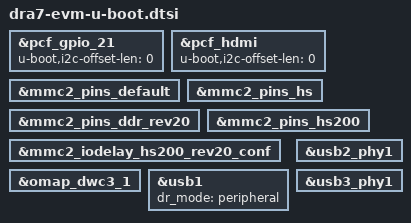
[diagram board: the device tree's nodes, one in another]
// SPDX-License-Identifier: GPL-2.0+
/*
 * Copyright (C) 2017 Texas Instruments Incorporated - https://www.ti.com/
 */

#include "omap5-u-boot.dtsi"

&pcf_gpio_21{
	u-boot,i2c-offset-len = <0>;
};

&pcf_hdmi{
	u-boot,i2c-offset-len = <0>;
};

&mmc2_pins_default {
	bootph-pre-ram;
};

&mmc2_pins_hs {
	bootph-pre-ram;
};

&mmc2_pins_ddr_rev20 {
	bootph-pre-ram;
};

&mmc2_pins_hs200 {
	bootph-pre-ram;
};

&mmc2_iodelay_hs200_rev20_conf {
	bootph-pre-ram;
};

&omap_dwc3_1 {
	bootph-pre-ram;
};

&usb1 {
	bootph-pre-ram;
	dr_mode = "peripheral";
};

&usb2_phy1 {
	bootph-pre-ram;
};

&usb3_phy1 {
	bootph-pre-ram;
};
